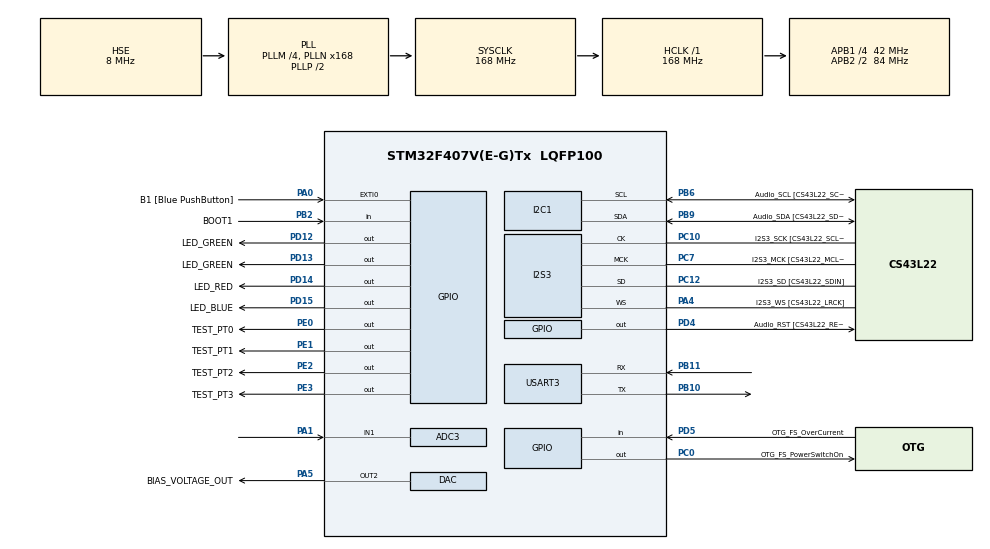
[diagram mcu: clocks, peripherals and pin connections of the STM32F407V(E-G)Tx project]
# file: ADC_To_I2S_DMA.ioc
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ADC3.Channel-0\#ChannelRegularConversion=ADC_CHANNEL_1
ADC3.DataAlign=ADC_DATAALIGN_LEFT
ADC3.ExternalTrigConv=ADC_EXTERNALTRIGCONV_T2_TRGO
ADC3.Rank-0\#ChannelRegularConversion=1
ADC3.SamplingTime-0\#ChannelRegularConversion=ADC_SAMPLETIME_56CYCLES
Dma.ADC3.3.Direction=DMA_PERIPH_TO_MEMORY
Dma.ADC3.3.FIFOMode=DMA_FIFOMODE_ENABLE
Dma.ADC3.3.FIFOThreshold=DMA_FIFO_THRESHOLD_HALFFULL
Dma.ADC3.3.Instance=DMA2_Stream0
Dma.ADC3.3.MemBurst=DMA_MBURST_INC4
Dma.ADC3.3.MemDataAlignment=DMA_MDATAALIGN_HALFWORD
Dma.ADC3.3.MemInc=DMA_MINC_ENABLE
Dma.ADC3.3.Mode=DMA_NORMAL
Dma.ADC3.3.PeriphBurst=DMA_PBURST_INC4
Dma.ADC3.3.PeriphDataAlignment=DMA_PDATAALIGN_HALFWORD
Dma.ADC3.3.PeriphInc=DMA_PINC_DISABLE
Dma.ADC3.3.Priority=DMA_PRIORITY_VERY_HIGH
Dma.I2C1_RX.0.Direction=DMA_PERIPH_TO_MEMORY
Dma.I2C1_RX.0.FIFOMode=DMA_FIFOMODE_DISABLE
Dma.I2C1_RX.0.Instance=DMA1_Stream0
Dma.I2C1_RX.0.MemDataAlignment=DMA_MDATAALIGN_BYTE
Dma.I2C1_RX.0.MemInc=DMA_MINC_ENABLE
Dma.I2C1_RX.0.Mode=DMA_NORMAL
Dma.I2C1_RX.0.PeriphDataAlignment=DMA_PDATAALIGN_BYTE
Dma.I2C1_RX.0.PeriphInc=DMA_PINC_DISABLE
Dma.I2C1_RX.0.Priority=DMA_PRIORITY_LOW
Dma.I2C1_TX.1.Direction=DMA_MEMORY_TO_PERIPH
Dma.I2C1_TX.1.FIFOMode=DMA_FIFOMODE_DISABLE
Dma.I2C1_TX.1.Instance=DMA1_Stream6
Dma.I2C1_TX.1.MemDataAlignment=DMA_MDATAALIGN_BYTE
Dma.I2C1_TX.1.MemInc=DMA_MINC_ENABLE
Dma.I2C1_TX.1.Mode=DMA_NORMAL
Dma.I2C1_TX.1.PeriphDataAlignment=DMA_PDATAALIGN_BYTE
Dma.I2C1_TX.1.PeriphInc=DMA_PINC_DISABLE
Dma.I2C1_TX.1.Priority=DMA_PRIORITY_LOW
Dma.Request0=I2C1_RX
Dma.Request1=I2C1_TX
Dma.Request2=SPI3_TX
Dma.Request3=ADC3
Dma.Request4=USART3_TX
Dma.SPI3_TX.2.Direction=DMA_MEMORY_TO_PERIPH
Dma.SPI3_TX.2.FIFOMode=DMA_FIFOMODE_ENABLE
Dma.SPI3_TX.2.FIFOThreshold=DMA_FIFO_THRESHOLD_HALFFULL
Dma.SPI3_TX.2.Instance=DMA1_Stream5
Dma.SPI3_TX.2.MemBurst=DMA_MBURST_INC4
Dma.SPI3_TX.2.MemDataAlignment=DMA_MDATAALIGN_HALFWORD
Dma.SPI3_TX.2.MemInc=DMA_MINC_ENABLE
Dma.SPI3_TX.2.Mode=DMA_CIRCULAR
Dma.SPI3_TX.2.PeriphBurst=DMA_PBURST_INC4
Dma.SPI3_TX.2.PeriphDataAlignment=DMA_PDATAALIGN_HALFWORD
Dma.SPI3_TX.2.PeriphInc=DMA_PINC_DISABLE
Dma.SPI3_TX.2.Priority=DMA_PRIORITY_HIGH
Dma.USART3_TX.4.Direction=DMA_MEMORY_TO_PERIPH
Dma.USART3_TX.4.FIFOMode=DMA_FIFOMODE_DISABLE
Dma.USART3_TX.4.Instance=DMA1_Stream3
Dma.USART3_TX.4.MemDataAlignment=DMA_MDATAALIGN_BYTE
Dma.USART3_TX.4.MemInc=DMA_MINC_ENABLE
Dma.USART3_TX.4.Mode=DMA_NORMAL
Dma.USART3_TX.4.PeriphDataAlignment=DMA_PDATAALIGN_BYTE
Dma.USART3_TX.4.PeriphInc=DMA_PINC_DISABLE
Dma.USART3_TX.4.Priority=DMA_PRIORITY_LOW
I2S3.AudioFreq=I2S_AUDIOFREQ_44K
I2S3.ErrorAudioFreq=0.07 %
I2S3.FullDuplexMode=I2S_FULLDUPLEXMODE_DISABLE
I2S3.Instance=SPI$Index
I2S3.RealAudioFreq=44.034 KHz
I2S3.VirtualMode=I2S_MODE_MASTER
Mcu.Family=STM32F4
Mcu.Name=STM32F407V(E-G)Tx
Mcu.Package=LQFP100
NVIC.DMA1_Stream0_IRQn=true\:0\:0\:false\:false\:true\:false\:true
NVIC.DMA1_Stream3_IRQn=true\:0\:0\:false\:false\:true\:false\:true
NVIC.DMA1_Stream5_IRQn=true\:0\:0\:false\:false\:true\:false\:true
NVIC.DMA1_Stream6_IRQn=true\:0\:0\:false\:false\:true\:false\:true
NVIC.DMA2_Stream0_IRQn=true\:0\:0\:false\:false\:true\:false\:true
NVIC.PriorityGroup=NVIC_PRIORITYGROUP_0
PA0-WKUP.GPIO_Label=B1 [Blue PushButton]
PA0-WKUP.Signal=GPXTI0
PA1.Signal=ADCx_IN1
PA4.GPIO_Label=I2S3_WS [CS43L22_LRCK]
PA4.GPIO_Mode=GPIO_MODE_AF_PP
PA4.GPIO_PuPd=GPIO_NOPULL
PA4.GPIO_Speed=GPIO_SPEED_FREQ_VERY_HIGH
PA4.Mode=Half_Duplex_Master
PA4.Signal=I2S3_WS
PA5.GPIO_Label=BIAS_VOLTAGE_OUT
PA5.Signal=COMP_DAC2_group
PB10.Mode=Asynchronous
PB10.Signal=USART3_TX
PB11.Mode=Asynchronous
PB11.Signal=USART3_RX
PB2.GPIO_Label=BOOT1
PB2.GPIO_Mode=GPIO_MODE_INPUT
PB2.GPIO_PuPd=GPIO_NOPULL
PB2.Signal=GPIO_Input
PB3.GPIO_Label=SWO
PB3.Signal=SYS_JTDO-SWO
PB6.GPIO_Label=Audio_SCL [CS43L22_SCL]
PB6.GPIO_Mode=GPIO_MODE_AF_OD
PB6.GPIO_PuPd=GPIO_NOPULL
PB6.GPIO_Speed=GPIO_SPEED_FREQ_LOW
PB6.Mode=I2C
PB6.Signal=I2C1_SCL
PB9.GPIO_Label=Audio_SDA [CS43L22_SDA]
PB9.GPIO_Mode=GPIO_MODE_AF_OD
PB9.GPIO_PuPd=GPIO_NOPULL
PB9.GPIO_Speed=GPIO_SPEED_FREQ_LOW
PB9.Mode=I2C
PB9.Signal=I2C1_SDA
PC0.GPIO_Label=OTG_FS_PowerSwitchOn
PC0.GPIO_PuPd=GPIO_NOPULL
PC0.GPIO_Speed=GPIO_SPEED_FREQ_LOW
PC0.PinState=GPIO_PIN_SET
PC0.Signal=GPIO_Output
PC10.GPIO_Label=I2S3_SCK [CS43L22_SCLK]
PC10.GPIO_Mode=GPIO_MODE_AF_PP
PC10.GPIO_PuPd=GPIO_NOPULL
PC10.GPIO_Speed=GPIO_SPEED_FREQ_VERY_HIGH
PC10.Mode=Half_Duplex_Master
PC10.Signal=I2S3_CK
PC12.GPIO_Label=I2S3_SD [CS43L22_SDIN]
PC12.GPIO_Mode=GPIO_MODE_AF_PP
PC12.GPIO_PuPd=GPIO_NOPULL
PC12.GPIO_Speed=GPIO_SPEED_FREQ_VERY_HIGH
PC12.Mode=Half_Duplex_Master
PC12.Signal=I2S3_SD
PC7.GPIO_Label=I2S3_MCK [CS43L22_MCLK]
PC7.GPIO_Mode=GPIO_MODE_AF_PP
PC7.GPIO_PuPd=GPIO_NOPULL
PC7.GPIO_Speed=GPIO_SPEED_FREQ_VERY_HIGH
PC7.Mode=Master_Clock_Activated
PC7.Signal=I2S3_MCK
PD12.GPIO_Label=LED_GREEN
PD12.GPIO_PuPd=GPIO_NOPULL
PD12.GPIO_Speed=GPIO_SPEED_FREQ_LOW
PD12.Signal=GPIO_Output
PD13.GPIO_Label=LED_GREEN
PD13.GPIO_PuPd=GPIO_NOPULL
PD13.GPIO_Speed=GPIO_SPEED_FREQ_LOW
PD13.Signal=GPIO_Output
PD14.GPIO_Label=LED_RED
PD14.GPIO_PuPd=GPIO_NOPULL
PD14.GPIO_Speed=GPIO_SPEED_FREQ_LOW
PD14.Signal=GPIO_Output
PD15.GPIO_Label=LED_BLUE
PD15.GPIO_PuPd=GPIO_NOPULL
PD15.GPIO_Speed=GPIO_SPEED_FREQ_LOW
PD15.Signal=GPIO_Output
PD4.GPIO_Label=Audio_RST [CS43L22_RESET]
PD4.GPIO_PuPd=GPIO_NOPULL
PD4.GPIO_Speed=GPIO_SPEED_FREQ_LOW
PD4.Signal=GPIO_Output
PD5.GPIO_Label=OTG_FS_OverCurrent
PD5.GPIO_Mode=GPIO_MODE_INPUT
PD5.GPIO_PuPd=GPIO_NOPULL
PD5.Signal=GPIO_Input
PE0.GPIO_Label=TEST_PT0
PE0.GPIO_ModeDefaultOutputPP=GPIO_MODE_OUTPUT_PP
PE0.GPIO_PuPd=GPIO_PULLDOWN
PE0.GPIO_Speed=GPIO_SPEED_FREQ_HIGH
PE0.PinState=GPIO_PIN_RESET
PE0.Signal=GPIO_Output
PE1.GPIO_Label=TEST_PT1
PE1.GPIO_ModeDefaultOutputPP=GPIO_MODE_OUTPUT_PP
PE1.GPIO_PuPd=GPIO_PULLDOWN
PE1.GPIO_Speed=GPIO_SPEED_FREQ_HIGH
PE1.PinState=GPIO_PIN_RESET
PE1.Signal=GPIO_Output
PE2.GPIO_Label=TEST_PT2
PE2.GPIO_ModeDefaultOutputPP=GPIO_MODE_OUTPUT_PP
PE2.GPIO_PuPd=GPIO_PULLDOWN
PE2.GPIO_Speed=GPIO_SPEED_FREQ_HIGH
PE2.PinState=GPIO_PIN_RESET
PE2.Signal=GPIO_Output
PE3.GPIO_Label=TEST_PT3
PE3.GPIO_ModeDefaultOutputPP=GPIO_MODE_OUTPUT_PP
PE3.GPIO_PuPd=GPIO_PULLDOWN
PE3.GPIO_Speed=GPIO_SPEED_FREQ_HIGH
PE3.PinState=GPIO_PIN_RESET
PE3.Signal=GPIO_Output
PH0-OSC_IN.GPIO_Label=PH0-OSC_IN
PH0-OSC_IN.Mode=HSE-External-Oscillator
PH0-OSC_IN.Signal=RCC_OSC_IN
PH1-OSC_OUT.GPIO_Label=PH1-OSC_OUT
PH1-OSC_OUT.Mode=HSE-External-Oscillator
PH1-OSC_OUT.Signal=RCC_OSC_OUT
ProjectManager.HeapSize=0x200
ProjectManager.StackSize=0x400
ProjectManager.TargetToolchain=STM32CubeIDE
RCC.48MHZClocksFreq_Value=48000000
RCC.AHBFreq_Value=168000000
RCC.APB1CLKDivider=RCC_HCLK_DIV4
RCC.APB1Freq_Value=42000000
RCC.APB1TimFreq_Value=84000000
RCC.APB2CLKDivider=RCC_HCLK_DIV2
RCC.APB2Freq_Value=84000000
RCC.APB2TimFreq_Value=168000000
RCC.CortexFreq_Value=168000000
RCC.HCLKFreq_Value=168000000
RCC.HSE_VALUE=8000000
RCC.HSI_VALUE=16000000
RCC.LSE_VALUE=32768
RCC.PLLI2SN=124
RCC.PLLM=4
RCC.PLLN=168
RCC.PLLQ=7
RCC.PLLSourceVirtual=RCC_PLLSOURCE_HSE
RCC.SYSCLKFreq_VALUE=168000000
RCC.SYSCLKSource=RCC_SYSCLKSOURCE_PLLCLK
RCC.VCOOutputFreq_Value=336000000
SH.ADCx_IN1.0=ADC3_IN1,IN1
SH.COMP_DAC2_group.0=DAC_OUT2,DAC_OUT2
TIM2.Period=630
TIM2.Prescaler=2
TIM2.TIM_MasterOutputTrigger=TIM_TRGO_UPDATE
USART3.VirtualMode=VM_ASYNC
VP_TIM2_VS_ClockSourceINT.Mode=Internal
board=STM32F407G-DISC1

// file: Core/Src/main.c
/* USER CODE BEGIN Header */
/**
  ******************************************************************************
  * @file           : main.c
  * @brief          : Main program body
  ******************************************************************************
  * @attention
  *
  * Copyright (c) 2021 STMicroelectronics.
  * All rights reserved.
  *
  * This software is licensed under terms that can be found in the LICENSE file
  * in the root directory of this software component.
  * If no LICENSE file comes with this software, it is provided AS-IS.
  *
  ******************************************************************************
  */
/* USER CODE END Header */
#include "main.h"
#include "adc.h"
#include "dac.h"
#include "dma.h"
#include "i2c.h"
#include "i2s.h"
#include "tim.h"
#include "usart.h"
#include "gpio.h"

/* USER CODE BEGIN Includes */
#include "audio.h"
/* USER CODE END Includes */

void SystemClock_Config(void);

int main(void)
{

  /* MCU Configuration--------------------------------------------------------*/

  /* Reset of all peripherals, Initializes the Flash interface and the Systick. */
  HAL_Init();

  /* Configure the system clock */
  SystemClock_Config();

  /* Initialize all configured peripherals */
  MX_GPIO_Init();
  MX_I2C1_Init();
  MX_DMA_Init();
  MX_I2S3_Init();
  MX_TIM2_Init();
  MX_ADC3_Init();
  MX_DAC_Init();
  MX_USART3_UART_Init();
  /* USER CODE BEGIN 2 */
  HAL_DAC_Start(&hdac, DAC1_CHANNEL_2);
  HAL_DAC_SetValue(&hdac, DAC_CHANNEL_2, DAC_ALIGN_12B_R, 512);
  Audio_Init();
  Audio_Loop();
  /* USER CODE END 2 */

  /* Infinite loop */
  while (1)
  {

  }
}

void SystemClock_Config(void)
{
  RCC_OscInitTypeDef RCC_OscInitStruct = {0};
  RCC_ClkInitTypeDef RCC_ClkInitStruct = {0};

  /** Configure the main internal regulator output voltage
  */
  __HAL_RCC_PWR_CLK_ENABLE();
  __HAL_PWR_VOLTAGESCALING_CONFIG(PWR_REGULATOR_VOLTAGE_SCALE1);
  /** Initializes the RCC Oscillators according to the specified parameters
  * in the RCC_OscInitTypeDef structure.
  */
  RCC_OscInitStruct.OscillatorType = RCC_OSCILLATORTYPE_HSE;
  RCC_OscInitStruct.HSEState = RCC_HSE_ON;
  RCC_OscInitStruct.PLL.PLLState = RCC_PLL_ON;
  RCC_OscInitStruct.PLL.PLLSource = RCC_PLLSOURCE_HSE;
  RCC_OscInitStruct.PLL.PLLM = 4;
  RCC_OscInitStruct.PLL.PLLN = 168;
  RCC_OscInitStruct.PLL.PLLP = RCC_PLLP_DIV2;
  RCC_OscInitStruct.PLL.PLLQ = 7;
  if (HAL_RCC_OscConfig(&RCC_OscInitStruct) != HAL_OK)
  {
    Error_Handler();
  }
  /** Initializes the CPU, AHB and APB buses clocks
  */
  RCC_ClkInitStruct.ClockType = RCC_CLOCKTYPE_HCLK|RCC_CLOCKTYPE_SYSCLK
                              |RCC_CLOCKTYPE_PCLK1|RCC_CLOCKTYPE_PCLK2;
  RCC_ClkInitStruct.SYSCLKSource = RCC_SYSCLKSOURCE_PLLCLK;
  RCC_ClkInitStruct.AHBCLKDivider = RCC_SYSCLK_DIV1;
  RCC_ClkInitStruct.APB1CLKDivider = RCC_HCLK_DIV4;
  RCC_ClkInitStruct.APB2CLKDivider = RCC_HCLK_DIV2;

  if (HAL_RCC_ClockConfig(&RCC_ClkInitStruct, FLASH_LATENCY_5) != HAL_OK)
  {
    Error_Handler();
  }
}

/* USER CODE BEGIN 4 */
int __io_putchar(int ch)
{
	uint8_t mychar = (uint8_t)(ch);
	HAL_UART_Transmit(&huart3, &mychar, 1,100);
	return ch;
}
/* USER CODE END 4 */

void Error_Handler(void)
{
  __disable_irq();
  while (1)
  {
  }
}
